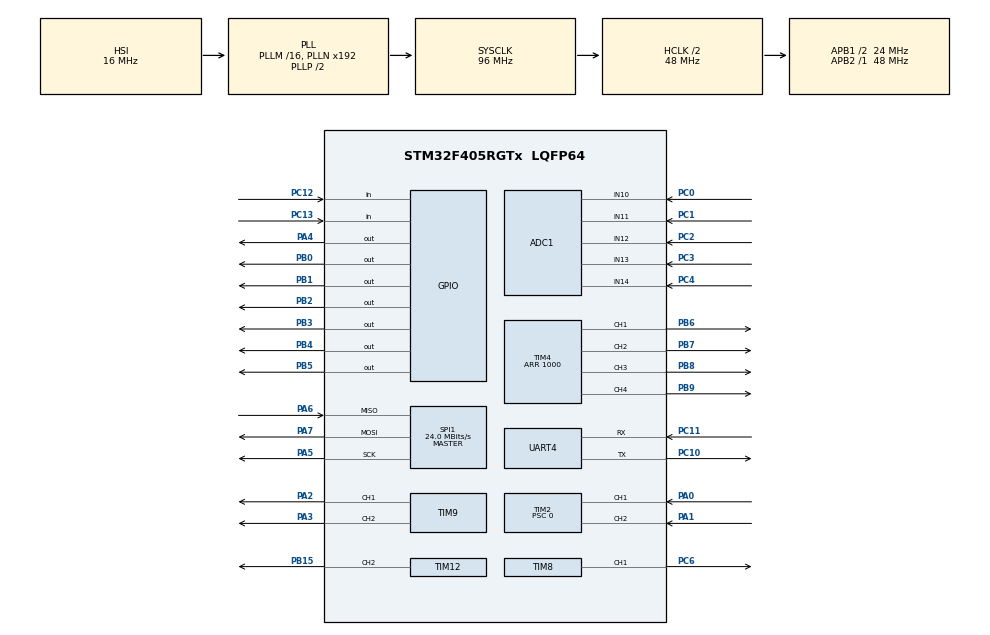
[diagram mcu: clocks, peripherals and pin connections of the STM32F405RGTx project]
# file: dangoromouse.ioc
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Mcu.Family=STM32F4
PA6.Mode=Full_Duplex_Master
RCC.CortexFreq_Value=48000000
SPI1.VirtualType=VM_MASTER
PC10.Signal=UART4_TX
PC12.Signal=GPIO_Input
PB15.Signal=S_TIM12_CH2
RCC.SYSCLKSource=RCC_SYSCLKSOURCE_PLLCLK
ProjectManager.StackSize=0x400
TIM1.Prescaler=30
SPI1.Direction=SPI_DIRECTION_2LINES
RCC.HCLKFreq_Value=48000000
TIM8.Channel-PWM\ Generation1\ CH1=TIM_CHANNEL_1
RCC.APB2TimFreq_Value=48000000
PB6.Signal=S_TIM4_CH1
SPI1.CalculateBaudRate=24.0 MBits/s
PC3.Signal=ADCx_IN13
RCC.AHBFreq_Value=48000000
ADC1.Channel-0\#ChannelRegularConversion=ADC_CHANNEL_10
RCC.HSE_VALUE=25000000
TIM4.Channel-PWM\ Generation3\ CH3=TIM_CHANNEL_3
PB2.Signal=GPIO_Output
PC13-ANTI_TAMP.Signal=GPIO_Input
PA14.Mode=Serial_Wire
SH.S_TIM4_CH2.0=TIM4_CH2,PWM Generation2 CH2
PB7.Signal=S_TIM4_CH2
TIM4.Period=1000
VP_TIM1_VS_ClockSourceINT.Mode=Internal
ADC1.SamplingTime-0\#ChannelRegularConversion=ADC_SAMPLETIME_3CYCLES
Mcu.Package=LQFP64
PB9.Signal=S_TIM4_CH4
TIM2.Prescaler=0
PB1.Signal=GPIO_Output
PA6.Signal=SPI1_MISO
SH.ADCx_IN14.0=ADC1_IN14,IN14
PC11.Mode=Asynchronous
SH.S_TIM12_CH2.0=TIM12_CH2,Output Compare2 CH2
SH.S_TIM4_CH1.0=TIM4_CH1,PWM Generation1 CH1
RCC.APB1TimFreq_Value=48000000
TIM1.Period=100-1
TIM4.Channel-PWM\ Generation4\ CH4=TIM_CHANNEL_4
SPI1.BaudRatePrescaler=SPI_BAUDRATEPRESCALER_2
PB4.Signal=GPIO_Output
PA3.Signal=S_TIM9_CH2
PA5.Mode=Full_Duplex_Master
TIM9.Channel-PWM\ Generation2\ CH2=TIM_CHANNEL_2
TIM4.Channel-PWM\ Generation1\ CH1=TIM_CHANNEL_1
TIM9.Channel-PWM\ Generation1\ CH1=TIM_CHANNEL_1
SH.ADCx_IN13.0=ADC1_IN13,IN13
ADC1.Rank-0\#ChannelRegularConversion=1
PA7.Mode=Full_Duplex_Master
SH.S_TIM4_CH4.0=TIM4_CH4,PWM Generation4 CH4
PC11.Signal=UART4_RX
PC2.Signal=ADCx_IN12
PC4.Signal=ADCx_IN14
PC6.Signal=S_TIM8_CH1
PC10.Mode=Asynchronous
PC0.Signal=ADCx_IN10
RCC.APB1CLKDivider=RCC_HCLK_DIV2
UART4.VirtualMode=Asynchronous
PA0-WKUP.Signal=S_TIM2_CH1_ETR
PA13.Signal=SYS_JTMS-SWDIO
SH.S_TIM2_CH2.0=TIM2_CH2,Encoder_Interface
SH.ADCx_IN12.0=ADC1_IN12,IN12
ProjectManager.TargetToolchain=STM32CubeIDE
SH.S_TIM9_CH2.0=TIM9_CH2,PWM Generation2 CH2
SH.S_TIM4_CH3.0=TIM4_CH3,PWM Generation3 CH3
RCC.LSE_VALUE=32768
PA1.Signal=S_TIM2_CH2
PA5.Signal=SPI1_SCK
SH.S_TIM8_CH1.0=TIM8_CH1,PWM Generation1 CH1
board=custom
RCC.VCOOutputFreq_Value=192000000
TIM4.Channel-PWM\ Generation2\ CH2=TIM_CHANNEL_2
RCC.APB2Freq_Value=48000000
SH.ADCx_IN11.0=ADC1_IN11,IN11
SPI1.Mode=SPI_MODE_MASTER
SH.S_TIM9_CH1.0=TIM9_CH1,PWM Generation1 CH1
RCC.AHBCLKDivider=RCC_SYSCLK_DIV2
TIM2.Period=65535
PA13.Mode=Serial_Wire
Mcu.Name=STM32F405RGTx
PA2.Signal=S_TIM9_CH1
PB3.Signal=GPIO_Output
PA4.Signal=GPIO_Output
RCC.SYSCLKFreq_VALUE=96000000
PB5.Signal=GPIO_Output
ADC1.master=1
SH.S_TIM2_CH1_ETR.0=TIM2_CH1,Encoder_Interface
PA14.Signal=SYS_JTCK-SWCLK
SH.ADCx_IN10.0=ADC1_IN10,IN10
ProjectManager.HeapSize=0x200
RCC.HSI_VALUE=16000000
NVIC.PriorityGroup=NVIC_PRIORITYGROUP_4
ADC1.NbrOfConversionFlag=1
PB8.Signal=S_TIM4_CH3
TIM12.Channel-Output\ Compare2\ CH2=TIM_CHANNEL_2
RCC.APB1Freq_Value=24000000
PB0.Signal=GPIO_Output
PC1.Signal=ADCx_IN11
PA7.Signal=SPI1_MOSI

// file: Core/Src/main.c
/* USER CODE BEGIN Header */
/**
  ******************************************************************************
  * @file           : main.c
  * @brief          : Main program body
  ******************************************************************************
  * @attention
  *
  * <h2><center>&copy; Copyright (c) 2022 STMicroelectronics.
  * All rights reserved.</center></h2>
  *
  * This software component is licensed by ST under BSD 3-Clause license,
  * the "License"; You may not use this file except in compliance with the
  * License. You may obtain a copy of the License at:
  *                        opensource.org/licenses/BSD-3-Clause
  *
  ******************************************************************************
  */
/* USER CODE END Header */
#include "main.h"

/* USER CODE BEGIN Includes */
#include "bmx055.h"
/* USER CODE END Includes */

ADC_HandleTypeDef hadc1;

SPI_HandleTypeDef hspi1;

TIM_HandleTypeDef htim1;
TIM_HandleTypeDef htim2;
TIM_HandleTypeDef htim4;
TIM_HandleTypeDef htim8;
TIM_HandleTypeDef htim9;
TIM_HandleTypeDef htim12;

UART_HandleTypeDef huart4;

void SystemClock_Config(void);
static void MX_GPIO_Init(void);
static void MX_ADC1_Init(void);
static void MX_SPI1_Init(void);
static void MX_TIM2_Init(void);
static void MX_TIM4_Init(void);
static void MX_TIM8_Init(void);
static void MX_TIM9_Init(void);
static void MX_TIM12_Init(void);
static void MX_UART4_Init(void);
static void MX_TIM1_Init(void);

int main(void)
{

  /* MCU Configuration--------------------------------------------------------*/

  /* Reset of all peripherals, Initializes the Flash interface and the Systick. */
  HAL_Init();

  /* Configure the system clock */
  SystemClock_Config();

  /* Initialize all configured peripherals */
  MX_GPIO_Init();
  MX_ADC1_Init();
  MX_SPI1_Init();
  MX_TIM2_Init();
  MX_TIM4_Init();
  MX_TIM8_Init();
  MX_TIM9_Init();
  MX_TIM12_Init();
  MX_UART4_Init();
  MX_TIM1_Init();
  /* USER CODE BEGIN 2 */
  extern float gz;
  GyroInit();
//  GyroOffsetCalc();
  /* USER CODE END 2 */

  /* Infinite loop */
  /* USER CODE BEGIN WHILE */
  while (1)
  {
//	  UpdateGyroData();
//	  printf("%f\r\n", gz);
//	  HAL_Delay(1000);
    /* USER CODE END WHILE */

  }
}

void SystemClock_Config(void)
{
  RCC_OscInitTypeDef RCC_OscInitStruct = {0};
  RCC_ClkInitTypeDef RCC_ClkInitStruct = {0};

  /** Configure the main internal regulator output voltage
  */
  __HAL_RCC_PWR_CLK_ENABLE();
  __HAL_PWR_VOLTAGESCALING_CONFIG(PWR_REGULATOR_VOLTAGE_SCALE1);
  /** Initializes the RCC Oscillators according to the specified parameters
  * in the RCC_OscInitTypeDef structure.
  */
  RCC_OscInitStruct.OscillatorType = RCC_OSCILLATORTYPE_HSI;
  RCC_OscInitStruct.HSIState = RCC_HSI_ON;
  RCC_OscInitStruct.HSICalibrationValue = RCC_HSICALIBRATION_DEFAULT;
  RCC_OscInitStruct.PLL.PLLState = RCC_PLL_ON;
  RCC_OscInitStruct.PLL.PLLSource = RCC_PLLSOURCE_HSI;
  RCC_OscInitStruct.PLL.PLLM = 16;
  RCC_OscInitStruct.PLL.PLLN = 192;
  RCC_OscInitStruct.PLL.PLLP = RCC_PLLP_DIV2;
  RCC_OscInitStruct.PLL.PLLQ = 4;
  if (HAL_RCC_OscConfig(&RCC_OscInitStruct) != HAL_OK)
  {
    Error_Handler();
  }
  /** Initializes the CPU, AHB and APB buses clocks
  */
  RCC_ClkInitStruct.ClockType = RCC_CLOCKTYPE_HCLK|RCC_CLOCKTYPE_SYSCLK
                              |RCC_CLOCKTYPE_PCLK1|RCC_CLOCKTYPE_PCLK2;
  RCC_ClkInitStruct.SYSCLKSource = RCC_SYSCLKSOURCE_PLLCLK;
  RCC_ClkInitStruct.AHBCLKDivider = RCC_SYSCLK_DIV2;
  RCC_ClkInitStruct.APB1CLKDivider = RCC_HCLK_DIV2;
  RCC_ClkInitStruct.APB2CLKDivider = RCC_HCLK_DIV1;

  if (HAL_RCC_ClockConfig(&RCC_ClkInitStruct, FLASH_LATENCY_1) != HAL_OK)
  {
    Error_Handler();
  }
}

static void MX_ADC1_Init(void)
{

  ADC_ChannelConfTypeDef sConfig = {0};

  /** Configure the global features of the ADC (Clock, Resolution, Data Alignment and number of conversion)
  */
  hadc1.Instance = ADC1;
  hadc1.Init.ClockPrescaler = ADC_CLOCK_SYNC_PCLK_DIV2;
  hadc1.Init.Resolution = ADC_RESOLUTION_12B;
  hadc1.Init.ScanConvMode = DISABLE;
  hadc1.Init.ContinuousConvMode = DISABLE;
  hadc1.Init.DiscontinuousConvMode = DISABLE;
  hadc1.Init.ExternalTrigConvEdge = ADC_EXTERNALTRIGCONVEDGE_NONE;
  hadc1.Init.ExternalTrigConv = ADC_SOFTWARE_START;
  hadc1.Init.DataAlign = ADC_DATAALIGN_RIGHT;
  hadc1.Init.NbrOfConversion = 1;
  hadc1.Init.DMAContinuousRequests = DISABLE;
  hadc1.Init.EOCSelection = ADC_EOC_SINGLE_CONV;
  if (HAL_ADC_Init(&hadc1) != HAL_OK)
  {
    Error_Handler();
  }
  /** Configure for the selected ADC regular channel its corresponding rank in the sequencer and its sample time.
  */
  sConfig.Channel = ADC_CHANNEL_10;
  sConfig.Rank = 1;
  sConfig.SamplingTime = ADC_SAMPLETIME_3CYCLES;
  if (HAL_ADC_ConfigChannel(&hadc1, &sConfig) != HAL_OK)
  {
    Error_Handler();
  }

}

static void MX_SPI1_Init(void)
{

  /* SPI1 parameter configuration*/
  hspi1.Instance = SPI1;
  hspi1.Init.Mode = SPI_MODE_MASTER;
  hspi1.Init.Direction = SPI_DIRECTION_2LINES;
  hspi1.Init.DataSize = SPI_DATASIZE_8BIT;
  hspi1.Init.CLKPolarity = SPI_POLARITY_LOW;
  hspi1.Init.CLKPhase = SPI_PHASE_1EDGE;
  hspi1.Init.NSS = SPI_NSS_SOFT;
  hspi1.Init.BaudRatePrescaler = SPI_BAUDRATEPRESCALER_2;
  hspi1.Init.FirstBit = SPI_FIRSTBIT_MSB;
  hspi1.Init.TIMode = SPI_TIMODE_DISABLE;
  hspi1.Init.CRCCalculation = SPI_CRCCALCULATION_DISABLE;
  hspi1.Init.CRCPolynomial = 10;
  if (HAL_SPI_Init(&hspi1) != HAL_OK)
  {
    Error_Handler();
  }

}

static void MX_TIM1_Init(void)
{

  TIM_ClockConfigTypeDef sClockSourceConfig = {0};
  TIM_MasterConfigTypeDef sMasterConfig = {0};

  htim1.Instance = TIM1;
  htim1.Init.Prescaler = 30;
  htim1.Init.CounterMode = TIM_COUNTERMODE_UP;
  htim1.Init.Period = 100-1;
  htim1.Init.ClockDivision = TIM_CLOCKDIVISION_DIV1;
  htim1.Init.RepetitionCounter = 0;
  htim1.Init.AutoReloadPreload = TIM_AUTORELOAD_PRELOAD_DISABLE;
  if (HAL_TIM_Base_Init(&htim1) != HAL_OK)
  {
    Error_Handler();
  }
  sClockSourceConfig.ClockSource = TIM_CLOCKSOURCE_INTERNAL;
  if (HAL_TIM_ConfigClockSource(&htim1, &sClockSourceConfig) != HAL_OK)
  {
    Error_Handler();
  }
  sMasterConfig.MasterOutputTrigger = TIM_TRGO_RESET;
  sMasterConfig.MasterSlaveMode = TIM_MASTERSLAVEMODE_DISABLE;
  if (HAL_TIMEx_MasterConfigSynchronization(&htim1, &sMasterConfig) != HAL_OK)
  {
    Error_Handler();
  }

}

static void MX_TIM2_Init(void)
{

  TIM_Encoder_InitTypeDef sConfig = {0};
  TIM_MasterConfigTypeDef sMasterConfig = {0};

  htim2.Instance = TIM2;
  htim2.Init.Prescaler = 0;
  htim2.Init.CounterMode = TIM_COUNTERMODE_UP;
  htim2.Init.Period = 65535;
  htim2.Init.ClockDivision = TIM_CLOCKDIVISION_DIV1;
  htim2.Init.AutoReloadPreload = TIM_AUTORELOAD_PRELOAD_DISABLE;
  sConfig.EncoderMode = TIM_ENCODERMODE_TI1;
  sConfig.IC1Polarity = TIM_ICPOLARITY_RISING;
  sConfig.IC1Selection = TIM_ICSELECTION_DIRECTTI;
  sConfig.IC1Prescaler = TIM_ICPSC_DIV1;
  sConfig.IC1Filter = 0;
  sConfig.IC2Polarity = TIM_ICPOLARITY_RISING;
  sConfig.IC2Selection = TIM_ICSELECTION_DIRECTTI;
  sConfig.IC2Prescaler = TIM_ICPSC_DIV1;
  sConfig.IC2Filter = 0;
  if (HAL_TIM_Encoder_Init(&htim2, &sConfig) != HAL_OK)
  {
    Error_Handler();
  }
  sMasterConfig.MasterOutputTrigger = TIM_TRGO_RESET;
  sMasterConfig.MasterSlaveMode = TIM_MASTERSLAVEMODE_DISABLE;
  if (HAL_TIMEx_MasterConfigSynchronization(&htim2, &sMasterConfig) != HAL_OK)
  {
    Error_Handler();
  }

}

static void MX_TIM4_Init(void)
{

  TIM_MasterConfigTypeDef sMasterConfig = {0};
  TIM_OC_InitTypeDef sConfigOC = {0};

  htim4.Instance = TIM4;
  htim4.Init.Prescaler = 0;
  htim4.Init.CounterMode = TIM_COUNTERMODE_UP;
  htim4.Init.Period = 1000;
  htim4.Init.ClockDivision = TIM_CLOCKDIVISION_DIV1;
  htim4.Init.AutoReloadPreload = TIM_AUTORELOAD_PRELOAD_DISABLE;
  if (HAL_TIM_PWM_Init(&htim4) != HAL_OK)
  {
    Error_Handler();
  }
  sMasterConfig.MasterOutputTrigger = TIM_TRGO_RESET;
  sMasterConfig.MasterSlaveMode = TIM_MASTERSLAVEMODE_DISABLE;
  if (HAL_TIMEx_MasterConfigSynchronization(&htim4, &sMasterConfig) != HAL_OK)
  {
    Error_Handler();
  }
  sConfigOC.OCMode = TIM_OCMODE_PWM1;
  sConfigOC.Pulse = 0;
  sConfigOC.OCPolarity = TIM_OCPOLARITY_HIGH;
  sConfigOC.OCFastMode = TIM_OCFAST_DISABLE;
  if (HAL_TIM_PWM_ConfigChannel(&htim4, &sConfigOC, TIM_CHANNEL_1) != HAL_OK)
  {
    Error_Handler();
  }
  if (HAL_TIM_PWM_ConfigChannel(&htim4, &sConfigOC, TIM_CHANNEL_2) != HAL_OK)
  {
    Error_Handler();
  }
  if (HAL_TIM_PWM_ConfigChannel(&htim4, &sConfigOC, TIM_CHANNEL_3) != HAL_OK)
  {
    Error_Handler();
  }
  if (HAL_TIM_PWM_ConfigChannel(&htim4, &sConfigOC, TIM_CHANNEL_4) != HAL_OK)
  {
    Error_Handler();
  }
  HAL_TIM_MspPostInit(&htim4);

}

static void MX_TIM8_Init(void)
{

  TIM_MasterConfigTypeDef sMasterConfig = {0};
  TIM_OC_InitTypeDef sConfigOC = {0};
  TIM_BreakDeadTimeConfigTypeDef sBreakDeadTimeConfig = {0};

  htim8.Instance = TIM8;
  htim8.Init.Prescaler = 0;
  htim8.Init.CounterMode = TIM_COUNTERMODE_UP;
  htim8.Init.Period = 65535;
  htim8.Init.ClockDivision = TIM_CLOCKDIVISION_DIV1;
  htim8.Init.RepetitionCounter = 0;
  htim8.Init.AutoReloadPreload = TIM_AUTORELOAD_PRELOAD_DISABLE;
  if (HAL_TIM_PWM_Init(&htim8) != HAL_OK)
  {
    Error_Handler();
  }
  sMasterConfig.MasterOutputTrigger = TIM_TRGO_RESET;
  sMasterConfig.MasterSlaveMode = TIM_MASTERSLAVEMODE_DISABLE;
  if (HAL_TIMEx_MasterConfigSynchronization(&htim8, &sMasterConfig) != HAL_OK)
  {
    Error_Handler();
  }
  sConfigOC.OCMode = TIM_OCMODE_PWM1;
  sConfigOC.Pulse = 0;
  sConfigOC.OCPolarity = TIM_OCPOLARITY_HIGH;
  sConfigOC.OCNPolarity = TIM_OCNPOLARITY_HIGH;
  sConfigOC.OCFastMode = TIM_OCFAST_DISABLE;
  sConfigOC.OCIdleState = TIM_OCIDLESTATE_RESET;
  sConfigOC.OCNIdleState = TIM_OCNIDLESTATE_RESET;
  if (HAL_TIM_PWM_ConfigChannel(&htim8, &sConfigOC, TIM_CHANNEL_1) != HAL_OK)
  {
    Error_Handler();
  }
  sBreakDeadTimeConfig.OffStateRunMode = TIM_OSSR_DISABLE;
  sBreakDeadTimeConfig.OffStateIDLEMode = TIM_OSSI_DISABLE;
  sBreakDeadTimeConfig.LockLevel = TIM_LOCKLEVEL_OFF;
  sBreakDeadTimeConfig.DeadTime = 0;
  sBreakDeadTimeConfig.BreakState = TIM_BREAK_DISABLE;
  sBreakDeadTimeConfig.BreakPolarity = TIM_BREAKPOLARITY_HIGH;
  sBreakDeadTimeConfig.AutomaticOutput = TIM_AUTOMATICOUTPUT_DISABLE;
  if (HAL_TIMEx_ConfigBreakDeadTime(&htim8, &sBreakDeadTimeConfig) != HAL_OK)
  {
    Error_Handler();
  }
  HAL_TIM_MspPostInit(&htim8);

}

static void MX_TIM9_Init(void)
{

  TIM_OC_InitTypeDef sConfigOC = {0};

  htim9.Instance = TIM9;
  htim9.Init.Prescaler = 0;
  htim9.Init.CounterMode = TIM_COUNTERMODE_UP;
  htim9.Init.Period = 65535;
  htim9.Init.ClockDivision = TIM_CLOCKDIVISION_DIV1;
  htim9.Init.AutoReloadPreload = TIM_AUTORELOAD_PRELOAD_DISABLE;
  if (HAL_TIM_PWM_Init(&htim9) != HAL_OK)
  {
    Error_Handler();
  }
  sConfigOC.OCMode = TIM_OCMODE_PWM1;
  sConfigOC.Pulse = 0;
  sConfigOC.OCPolarity = TIM_OCPOLARITY_HIGH;
  sConfigOC.OCFastMode = TIM_OCFAST_DISABLE;
  if (HAL_TIM_PWM_ConfigChannel(&htim9, &sConfigOC, TIM_CHANNEL_1) != HAL_OK)
  {
    Error_Handler();
  }
  if (HAL_TIM_PWM_ConfigChannel(&htim9, &sConfigOC, TIM_CHANNEL_2) != HAL_OK)
  {
    Error_Handler();
  }
  HAL_TIM_MspPostInit(&htim9);

}

static void MX_TIM12_Init(void)
{

  TIM_OC_InitTypeDef sConfigOC = {0};

  htim12.Instance = TIM12;
  htim12.Init.Prescaler = 0;
  htim12.Init.CounterMode = TIM_COUNTERMODE_UP;
  htim12.Init.Period = 65535;
  htim12.Init.ClockDivision = TIM_CLOCKDIVISION_DIV1;
  htim12.Init.AutoReloadPreload = TIM_AUTORELOAD_PRELOAD_DISABLE;
  if (HAL_TIM_OC_Init(&htim12) != HAL_OK)
  {
    Error_Handler();
  }
  sConfigOC.OCMode = TIM_OCMODE_TIMING;
  sConfigOC.Pulse = 0;
  sConfigOC.OCPolarity = TIM_OCPOLARITY_HIGH;
  sConfigOC.OCFastMode = TIM_OCFAST_DISABLE;
  if (HAL_TIM_OC_ConfigChannel(&htim12, &sConfigOC, TIM_CHANNEL_2) != HAL_OK)
  {
    Error_Handler();
  }
  HAL_TIM_MspPostInit(&htim12);

}

static void MX_UART4_Init(void)
{

  huart4.Instance = UART4;
  huart4.Init.BaudRate = 115200;
  huart4.Init.WordLength = UART_WORDLENGTH_8B;
  huart4.Init.StopBits = UART_STOPBITS_1;
  huart4.Init.Parity = UART_PARITY_NONE;
  huart4.Init.Mode = UART_MODE_TX_RX;
  huart4.Init.HwFlowCtl = UART_HWCONTROL_NONE;
  huart4.Init.OverSampling = UART_OVERSAMPLING_16;
  if (HAL_UART_Init(&huart4) != HAL_OK)
  {
    Error_Handler();
  }

}

static void MX_GPIO_Init(void)
{
  GPIO_InitTypeDef GPIO_InitStruct = {0};

  /* GPIO Ports Clock Enable */
  __HAL_RCC_GPIOC_CLK_ENABLE();
  __HAL_RCC_GPIOA_CLK_ENABLE();
  __HAL_RCC_GPIOB_CLK_ENABLE();

  /*Configure GPIO pin Output Level */
  HAL_GPIO_WritePin(GPIOA, GPIO_PIN_4, GPIO_PIN_RESET);

  /*Configure GPIO pin Output Level */
  HAL_GPIO_WritePin(GPIOB, GPIO_PIN_0|GPIO_PIN_1|GPIO_PIN_2|GPIO_PIN_3
                          |GPIO_PIN_4|GPIO_PIN_5, GPIO_PIN_RESET);

  /*Configure GPIO pins : PC13 PC12 */
  GPIO_InitStruct.Pin = GPIO_PIN_13|GPIO_PIN_12;
  GPIO_InitStruct.Mode = GPIO_MODE_INPUT;
  GPIO_InitStruct.Pull = GPIO_NOPULL;
  HAL_GPIO_Init(GPIOC, &GPIO_InitStruct);

  /*Configure GPIO pin : PA4 */
  GPIO_InitStruct.Pin = GPIO_PIN_4;
  GPIO_InitStruct.Mode = GPIO_MODE_OUTPUT_PP;
  GPIO_InitStruct.Pull = GPIO_NOPULL;
  GPIO_InitStruct.Speed = GPIO_SPEED_FREQ_LOW;
  HAL_GPIO_Init(GPIOA, &GPIO_InitStruct);

  /*Configure GPIO pins : PB0 PB1 PB2 PB3
                           PB4 PB5 */
  GPIO_InitStruct.Pin = GPIO_PIN_0|GPIO_PIN_1|GPIO_PIN_2|GPIO_PIN_3
                          |GPIO_PIN_4|GPIO_PIN_5;
  GPIO_InitStruct.Mode = GPIO_MODE_OUTPUT_PP;
  GPIO_InitStruct.Pull = GPIO_NOPULL;
  GPIO_InitStruct.Speed = GPIO_SPEED_FREQ_LOW;
  HAL_GPIO_Init(GPIOB, &GPIO_InitStruct);

}

void Error_Handler(void)
{
  __disable_irq();
  while (1)
  {
  }
}

/************************ (C) COPYRIGHT STMicroelectronics *****END OF FILE****/
